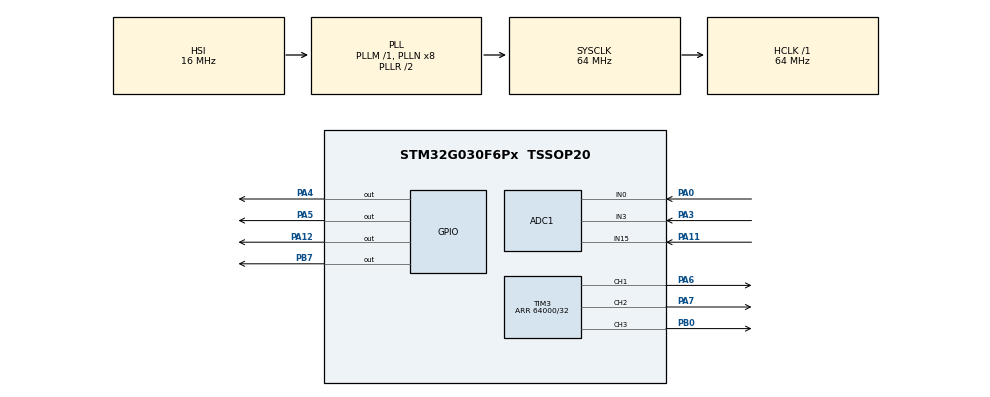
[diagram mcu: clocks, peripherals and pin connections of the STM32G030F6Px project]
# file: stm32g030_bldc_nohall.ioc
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ADC1.ClockPrescaler=ADC_CLOCK_SYNC_PCLK_DIV4
ADC1.ContinuousConvMode=DISABLE
ADC1.DMAContinuousRequests=ENABLE
ADC1.DiscontinuousConvMode=ENABLE
ADC1.EOCSelection=ADC_EOC_SEQ_CONV
ADC1.ExternalTrigConv=ADC_EXTERNALTRIG_T3_TRGO
ADC1.ExternalTrigConvEdge=ADC_EXTERNALTRIGCONVEDGE_RISING
ADC1.NbrOfConversion=1
ADC1.NbrOfConversionFlag=0
ADC1.SamplingTimeCommon1=ADC_SAMPLETIME_7CYCLES_5
ADC1.SelectedChannel=ADC_CHANNEL_0|ADC_CHANNEL_3|ADC_CHANNEL_TEMPSENSOR|ADC_CHANNEL_15
ADC1.Sequencer=NOT_FULLY_CONFIGURABLE
ADC1.master=1
Dma.ADC1.0.Direction=DMA_PERIPH_TO_MEMORY
Dma.ADC1.0.EventEnable=DISABLE
Dma.ADC1.0.Instance=DMA1_Channel1
Dma.ADC1.0.MemDataAlignment=DMA_MDATAALIGN_HALFWORD
Dma.ADC1.0.MemInc=DMA_MINC_ENABLE
Dma.ADC1.0.Mode=DMA_CIRCULAR
Dma.ADC1.0.PeriphDataAlignment=DMA_PDATAALIGN_HALFWORD
Dma.ADC1.0.PeriphInc=DMA_PINC_DISABLE
Dma.ADC1.0.Polarity=HAL_DMAMUX_REQ_GEN_RISING
Dma.ADC1.0.Priority=DMA_PRIORITY_HIGH
Dma.ADC1.0.RequestNumber=1
Dma.ADC1.0.SignalID=NONE
Dma.ADC1.0.SyncEnable=DISABLE
Dma.ADC1.0.SyncPolarity=HAL_DMAMUX_SYNC_NO_EVENT
Dma.ADC1.0.SyncRequestNumber=1
Dma.ADC1.0.SyncSignalID=NONE
Dma.Request0=ADC1
Mcu.Family=STM32G0
Mcu.Name=STM32G030F6Px
Mcu.Package=TSSOP20
NVIC.DMA1_Channel1_IRQn=true\:1\:0\:true\:false\:true\:false\:true\:true
NVIC.TIM16_IRQn=true\:0\:0\:false\:false\:true\:true\:true\:true
PA0.Mode=IN0
PA0.Signal=ADC1_IN0
PA11\ [PA9].Mode=IN15
PA11\ [PA9].Signal=ADC1_IN15
PA12\ [PA10].PinState=GPIO_PIN_SET
PA12\ [PA10].Signal=GPIO_Output
PA13.Mode=Serial_Wire
PA13.Signal=SYS_SWDIO
PA14-BOOT0.Mode=Serial_Wire
PA14-BOOT0.Signal=SYS_SWCLK
PA14-BOOT0__PA15.StandardMode=true
PA3.Mode=IN3
PA3.Signal=ADC1_IN3
PA4.PinState=GPIO_PIN_SET
PA4.Signal=GPIO_Output
PA5.PinState=GPIO_PIN_SET
PA5.Signal=GPIO_Output
PA6.Signal=S_TIM3_CH1
PA7.Signal=S_TIM3_CH2
PB0.Signal=S_TIM3_CH3
PB0__PB1__PB2__PA8.StandardMode=true
PB3__PB4__PB5__PB6.StandardMode=true
PB7.Signal=GPIO_Output
PB7__PB8.StandardMode=true
PC14-OSC32_IN\ (PC14)__PB9.StandardMode=true
ProjectManager.HeapSize=0x200
ProjectManager.StackSize=0x400
ProjectManager.TargetToolchain=MDK-ARM V5.32
RCC.ADCFreq_Value=64000000
RCC.AHBFreq_Value=64000000
RCC.CortexFreq_Value=64000000
RCC.EXTERNAL_CLOCK_VALUE=12288000
RCC.HCLKFreq_Value=64000000
RCC.HSE_VALUE=8000000
RCC.HSI_VALUE=16000000
RCC.LSE_VALUE=32768
RCC.SYSCLKFreq_VALUE=64000000
RCC.SYSCLKSource=RCC_SYSCLKSOURCE_PLLCLK
RCC.VCOOutputFreq_Value=128000000
SH.S_TIM3_CH1.0=TIM3_CH1,PWM Generation1 CH1
SH.S_TIM3_CH2.0=TIM3_CH2,PWM Generation2 CH2
SH.S_TIM3_CH3.0=TIM3_CH3,PWM Generation3 CH3
TIM14.Period=60000-1
TIM14.Prescaler=64-1
TIM16.Period=100-1
TIM16.Prescaler=64-1
TIM3.Channel-PWM\ Generation1\ CH1=TIM_CHANNEL_1
TIM3.Channel-PWM\ Generation2\ CH2=TIM_CHANNEL_2
TIM3.Channel-PWM\ Generation3\ CH3=TIM_CHANNEL_3
TIM3.Channel-PWM\ Generation4\ No\ Output=TIM_CHANNEL_4
TIM3.CounterMode=TIM_COUNTERMODE_CENTERALIGNED1
TIM3.OCFastMode_PWM-PWM\ Generation1\ CH1=TIM_OCFAST_ENABLE
TIM3.OCFastMode_PWM-PWM\ Generation2\ CH2=TIM_OCFAST_ENABLE
TIM3.OCFastMode_PWM-PWM\ Generation3\ CH3=TIM_OCFAST_ENABLE
TIM3.OCFastMode_PWM-PWM\ Generation4\ No\ Output=TIM_OCFAST_ENABLE
TIM3.OCMode_PWM-PWM\ Generation4\ No\ Output=TIM_OCMODE_PWM2
TIM3.Period=64000/32
TIM3.Pulse-PWM\ Generation1\ CH1=1000
TIM3.Pulse-PWM\ Generation2\ CH2=1000
TIM3.Pulse-PWM\ Generation3\ CH3=1000
TIM3.Pulse-PWM\ Generation4\ No\ Output=1
TIM3.TIM_MasterOutputTrigger=TIM_TRGO_OC4REF
VP_ADC1_TempSens_Input.Mode=IN-TempSens
VP_TIM14_VS_ClockSourceINT.Mode=Enable_Timer
VP_TIM16_VS_ClockSourceINT.Mode=Enable_Timer
VP_TIM3_VS_ClockSourceINT.Mode=Internal
VP_TIM3_VS_no_output4.Mode=PWM Generation4 No Output
board=custom

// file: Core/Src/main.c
/* USER CODE BEGIN Header */
/**
  ******************************************************************************
  * @file           : main.c
  * @brief          : Main program body
  ******************************************************************************
  * @attention
  *
  * Copyright (c) 2023 STMicroelectronics.
  * All rights reserved.
  *
  * This software is licensed under terms that can be found in the LICENSE file
  * in the root directory of this software component.
  * If no LICENSE file comes with this software, it is provided AS-IS.
  *
  ******************************************************************************
  */
/* USER CODE END Header */
#include "main.h"
#include "adc.h"
#include "dma.h"
#include "tim.h"
#include "gpio.h"

/* USER CODE BEGIN Includes */
#include "bldc.h"
/* USER CODE END Includes */

void SystemClock_Config(void);

int main(void)
{

  /* MCU Configuration--------------------------------------------------------*/

  /* Reset of all peripherals, Initializes the Flash interface and the Systick. */
  HAL_Init();

  /* Configure the system clock */
  SystemClock_Config();

  /* Initialize all configured peripherals */
  MX_GPIO_Init();
  MX_DMA_Init();
  MX_ADC1_Init();
  MX_TIM3_Init();
  MX_TIM14_Init();
  MX_TIM16_Init();
  /* USER CODE BEGIN 2 */
  // bldc_parameters_init(&bldc_parameters);
  // bldc_flags_init(&bldc_flags);
  // pid_speed_init(&pid_speed);
  // bldc_zc_parameters_init(&bldc_zc_parameters);
  // bldc_startup_parameters_init(&bldc_startup_parameters);
  HAL_TIM_PWM_Start(&htim3, TIM_CHANNEL_4);     // TIM3_CHANNEL4触发ADC采集
  HAL_ADCEx_Calibration_Start(&hadc1);          // adc1校准
  HAL_ADC_Start_DMA(&hadc1, (uint32_t*)adc1_value, ADC1_CHANNEL_CNT);
  __HAL_TIM_ENABLE_IT(&htim16, TIM_IT_UPDATE);  // 使能TIM16的更新中断
  bldc_parameters.status = BLDC_INIT_0;
  /* USER CODE END 2 */

  /* Infinite loop */
  while (1)
  {

  }
}

void SystemClock_Config(void)
{
  RCC_OscInitTypeDef RCC_OscInitStruct = {0};
  RCC_ClkInitTypeDef RCC_ClkInitStruct = {0};

  /** Configure the main internal regulator output voltage
  */
  HAL_PWREx_ControlVoltageScaling(PWR_REGULATOR_VOLTAGE_SCALE1);

  /** Initializes the RCC Oscillators according to the specified parameters
  * in the RCC_OscInitTypeDef structure.
  */
  RCC_OscInitStruct.OscillatorType = RCC_OSCILLATORTYPE_HSI;
  RCC_OscInitStruct.HSIState = RCC_HSI_ON;
  RCC_OscInitStruct.HSIDiv = RCC_HSI_DIV1;
  RCC_OscInitStruct.HSICalibrationValue = RCC_HSICALIBRATION_DEFAULT;
  RCC_OscInitStruct.PLL.PLLState = RCC_PLL_ON;
  RCC_OscInitStruct.PLL.PLLSource = RCC_PLLSOURCE_HSI;
  RCC_OscInitStruct.PLL.PLLM = RCC_PLLM_DIV1;
  RCC_OscInitStruct.PLL.PLLN = 8;
  RCC_OscInitStruct.PLL.PLLP = RCC_PLLP_DIV2;
  RCC_OscInitStruct.PLL.PLLR = RCC_PLLR_DIV2;
  if (HAL_RCC_OscConfig(&RCC_OscInitStruct) != HAL_OK)
  {
    Error_Handler();
  }

  /** Initializes the CPU, AHB and APB buses clocks
  */
  RCC_ClkInitStruct.ClockType = RCC_CLOCKTYPE_HCLK|RCC_CLOCKTYPE_SYSCLK
                              |RCC_CLOCKTYPE_PCLK1;
  RCC_ClkInitStruct.SYSCLKSource = RCC_SYSCLKSOURCE_PLLCLK;
  RCC_ClkInitStruct.AHBCLKDivider = RCC_SYSCLK_DIV1;
  RCC_ClkInitStruct.APB1CLKDivider = RCC_HCLK_DIV1;

  if (HAL_RCC_ClockConfig(&RCC_ClkInitStruct, FLASH_LATENCY_2) != HAL_OK)
  {
    Error_Handler();
  }
}

void Error_Handler(void)
{
  __disable_irq();
  while (1)
  {
  }
}
